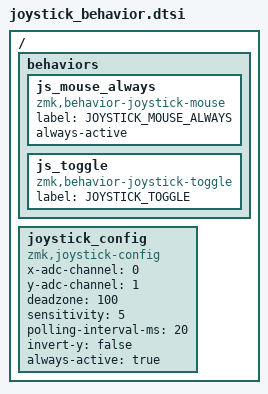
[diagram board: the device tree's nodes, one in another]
/ {
    behaviors {
        js_mouse_always: js_mouse_always {
            compatible = "zmk,behavior-joystick-mouse";
            label = "JOYSTICK_MOUSE_ALWAYS";
            #binding-cells = <0>;
            always-active;
        };
        
        js_toggle: js_toggle {
            compatible = "zmk,behavior-joystick-toggle";
            label = "JOYSTICK_TOGGLE";
            #binding-cells = <0>;
        };
    };
    
    joystick_config: joystick_config {
        compatible = "zmk,joystick-config";
        status = "okay";
        
        x-adc-channel = <0>;
        y-adc-channel = <1>;
        
        deadzone = <100>;
        sensitivity = <5>;
        polling-interval-ms = <20>;
        invert-y = <false>;
        always-active = <true>;
    };
};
